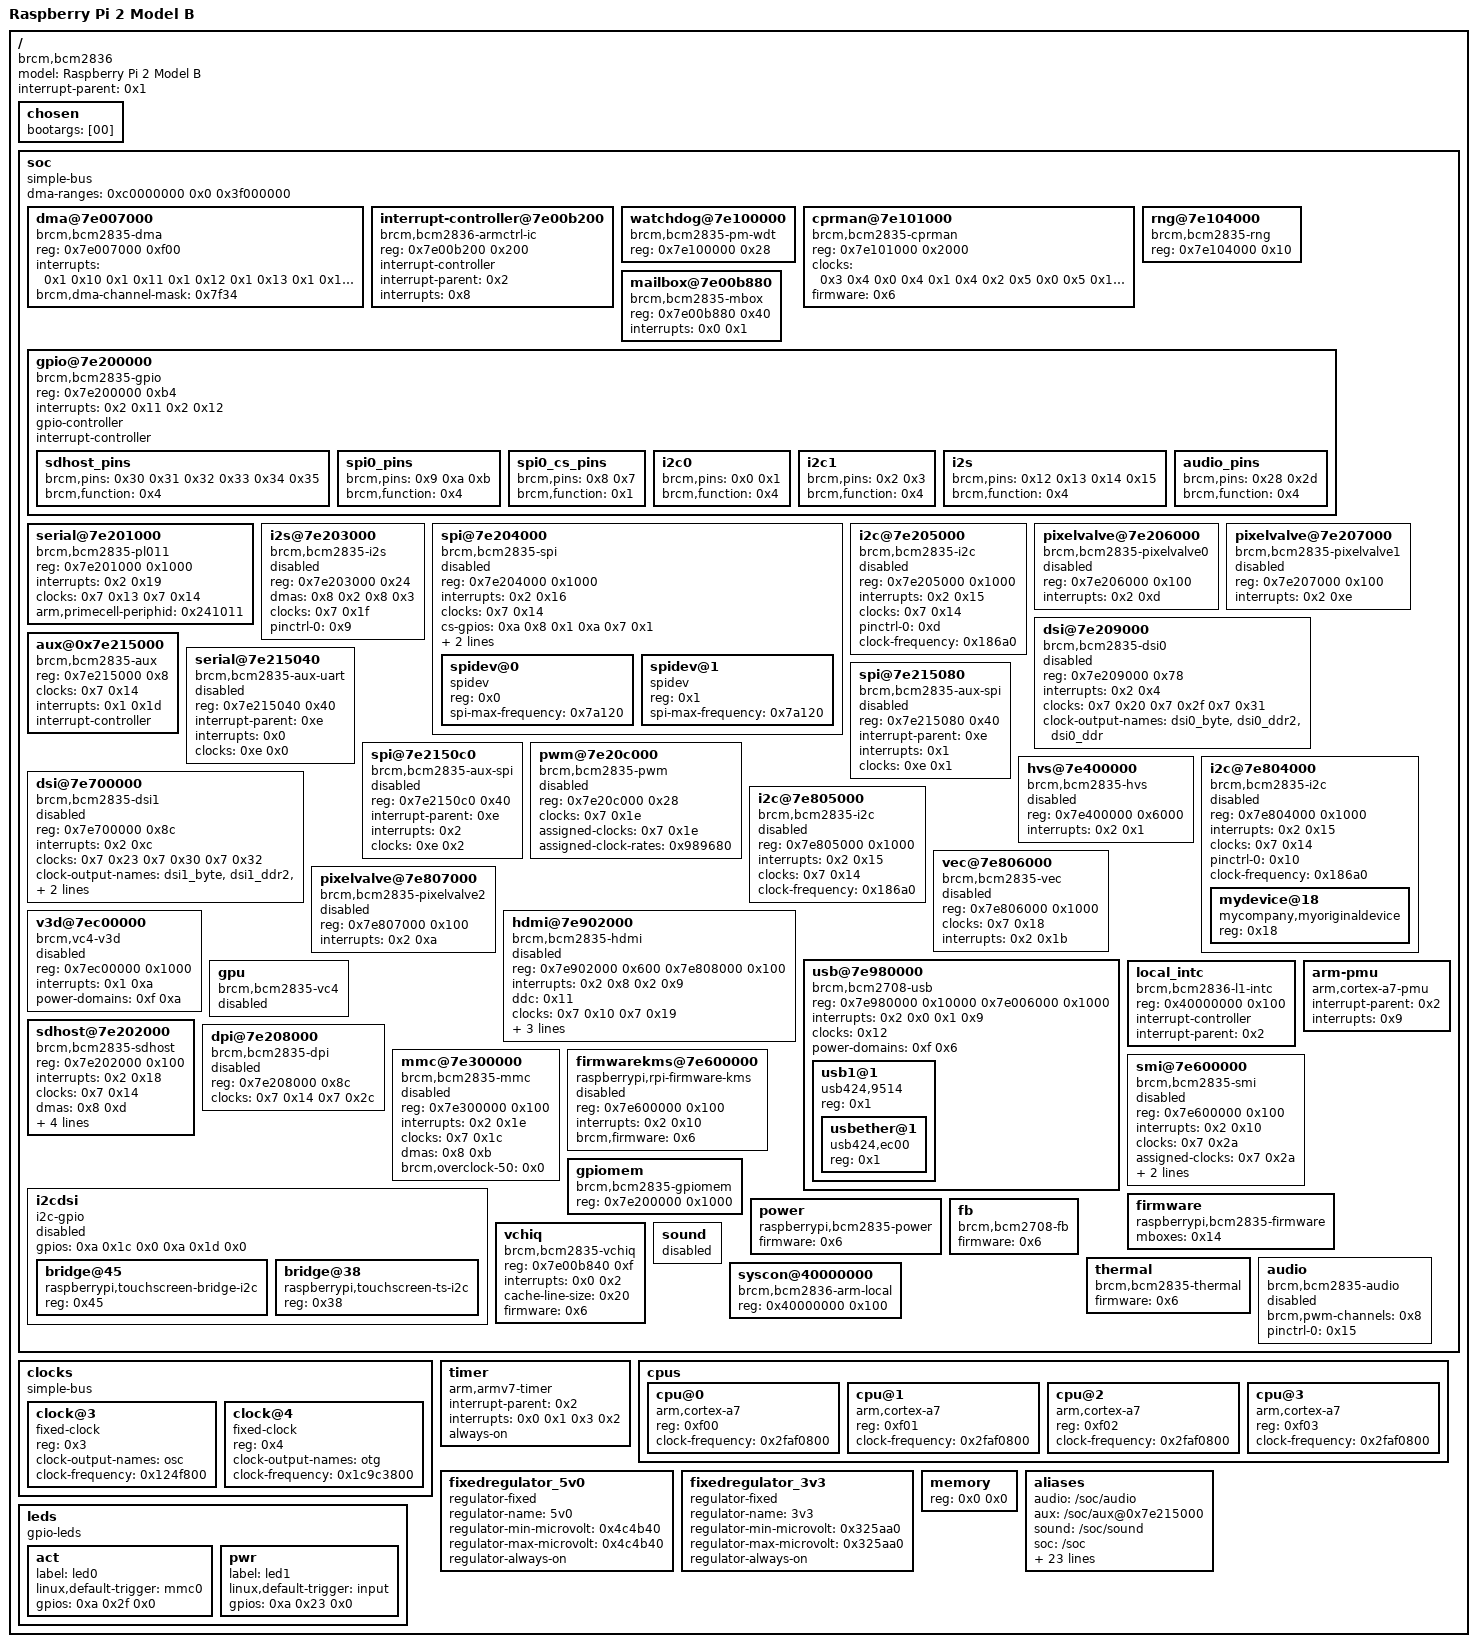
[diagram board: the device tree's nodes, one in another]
/dts-v1/;

/memreserve/	0x0000000000000000 0x0000000000001000;
/ {
	compatible = "brcm,bcm2836";
	model = "Raspberry Pi 2 Model B";
	interrupt-parent = <0x1>;
	#address-cells = <0x1>;
	#size-cells = <0x1>;

	chosen {
		bootargs = [00];
	};

	soc {
		compatible = "simple-bus";
		#address-cells = <0x1>;
		#size-cells = <0x1>;
		ranges = <0x7e000000 0x3f000000 0x1000000 0x40000000 0x40000000 0x40000>;
		dma-ranges = <0xc0000000 0x0 0x3f000000>;
		phandle = <0x27>;

		dma@7e007000 {
			compatible = "brcm,bcm2835-dma";
			reg = <0x7e007000 0xf00>;
			interrupts = <0x1 0x10 0x1 0x11 0x1 0x12 0x1 0x13 0x1 0x14 0x1 0x15 0x1 0x16 0x1 0x17 0x1 0x18 0x1 0x19 0x1 0x1a 0x1 0x1b 0x1 0x1b 0x1 0x1b 0x1 0x1b 0x1 0x1c>;
			interrupt-names = "dma0", "dma1", "dma2", "dma3", "dma4", "dma5", "dma6", "dma7", "dma8", "dma9", "dma10", "dma11", "dma12", "dma13", "dma14", "dma-shared-all";
			#dma-cells = <0x1>;
			brcm,dma-channel-mask = <0x7f34>;
			phandle = <0x8>;
		};

		interrupt-controller@7e00b200 {
			compatible = "brcm,bcm2836-armctrl-ic";
			reg = <0x7e00b200 0x200>;
			interrupt-controller;
			#interrupt-cells = <0x2>;
			interrupt-parent = <0x2>;
			interrupts = <0x8>;
			phandle = <0x1>;
		};

		watchdog@7e100000 {
			compatible = "brcm,bcm2835-pm-wdt";
			reg = <0x7e100000 0x28>;
			phandle = <0x24>;
		};

		cprman@7e101000 {
			compatible = "brcm,bcm2835-cprman";
			#clock-cells = <0x1>;
			reg = <0x7e101000 0x2000>;
			clocks = <0x3 0x4 0x0 0x4 0x1 0x4 0x2 0x5 0x0 0x5 0x1 0x5 0x2>;
			firmware = <0x6>;
			phandle = <0x7>;
		};

		rng@7e104000 {
			compatible = "brcm,bcm2835-rng";
			reg = <0x7e104000 0x10>;
			phandle = <0x25>;
		};

		mailbox@7e00b880 {
			compatible = "brcm,bcm2835-mbox";
			reg = <0x7e00b880 0x40>;
			interrupts = <0x0 0x1>;
			#mbox-cells = <0x0>;
			phandle = <0x14>;
		};

		gpio@7e200000 {
			compatible = "brcm,bcm2835-gpio";
			reg = <0x7e200000 0xb4>;
			interrupts = <0x2 0x11 0x2 0x12>;
			gpio-controller;
			#gpio-cells = <0x2>;
			interrupt-controller;
			#interrupt-cells = <0x2>;
			phandle = <0xa>;

			sdhost_pins {
				brcm,pins = <0x30 0x31 0x32 0x33 0x34 0x35>;
				brcm,function = <0x4>;
				phandle = <0x13>;
			};

			spi0_pins {
				brcm,pins = <0x9 0xa 0xb>;
				brcm,function = <0x4>;
				phandle = <0xb>;
			};

			spi0_cs_pins {
				brcm,pins = <0x8 0x7>;
				brcm,function = <0x1>;
				phandle = <0xc>;
			};

			i2c0 {
				brcm,pins = <0x0 0x1>;
				brcm,function = <0x4>;
				phandle = <0xd>;
			};

			i2c1 {
				brcm,pins = <0x2 0x3>;
				brcm,function = <0x4>;
				phandle = <0x10>;
			};

			i2s {
				brcm,pins = <0x12 0x13 0x14 0x15>;
				brcm,function = <0x4>;
				phandle = <0x9>;
			};

			audio_pins {
				brcm,pins = <0x28 0x2d>;
				brcm,function = <0x4>;
				phandle = <0x15>;
			};
		};

		serial@7e201000 {
			compatible = "brcm,bcm2835-pl011", "arm,pl011", "arm,primecell";
			reg = <0x7e201000 0x1000>;
			interrupts = <0x2 0x19>;
			clocks = <0x7 0x13 0x7 0x14>;
			clock-names = "uartclk", "apb_pclk";
			arm,primecell-periphid = <0x241011>;
			status = "okay";
			phandle = <0x1b>;
		};

		i2s@7e203000 {
			compatible = "brcm,bcm2835-i2s";
			reg = <0x7e203000 0x24>;
			dmas = <0x8 0x2 0x8 0x3>;
			dma-names = "tx", "rx";
			status = "disabled";
			#sound-dai-cells = <0x0>;
			clocks = <0x7 0x1f>;
			pinctrl-names = "default";
			pinctrl-0 = <0x9>;
			phandle = <0x1d>;
		};

		spi@7e204000 {
			compatible = "brcm,bcm2835-spi";
			reg = <0x7e204000 0x1000>;
			interrupts = <0x2 0x16>;
			clocks = <0x7 0x14>;
			#address-cells = <0x1>;
			#size-cells = <0x0>;
			status = "disabled";
			cs-gpios = <0xa 0x8 0x1 0xa 0x7 0x1>;
			dmas = <0x8 0x6 0x8 0x7>;
			dma-names = "tx", "rx";
			pinctrl-names = "default";
			pinctrl-0 = <0xb 0xc>;
			phandle = <0x1e>;

			spidev@0 {
				compatible = "spidev";
				reg = <0x0>;
				#address-cells = <0x1>;
				#size-cells = <0x0>;
				spi-max-frequency = <0x7a120>;
				phandle = <0x28>;
			};

			spidev@1 {
				compatible = "spidev";
				reg = <0x1>;
				#address-cells = <0x1>;
				#size-cells = <0x0>;
				spi-max-frequency = <0x7a120>;
				phandle = <0x29>;
			};
		};

		i2c@7e205000 {
			compatible = "brcm,bcm2835-i2c";
			reg = <0x7e205000 0x1000>;
			interrupts = <0x2 0x15>;
			clocks = <0x7 0x14>;
			#address-cells = <0x1>;
			#size-cells = <0x0>;
			status = "disabled";
			pinctrl-names = "default";
			pinctrl-0 = <0xd>;
			clock-frequency = <0x186a0>;
			phandle = <0x1f>;
		};

		pixelvalve@7e206000 {
			compatible = "brcm,bcm2835-pixelvalve0";
			reg = <0x7e206000 0x100>;
			interrupts = <0x2 0xd>;
			status = "disabled";
			phandle = <0x2a>;
		};

		pixelvalve@7e207000 {
			compatible = "brcm,bcm2835-pixelvalve1";
			reg = <0x7e207000 0x100>;
			interrupts = <0x2 0xe>;
			status = "disabled";
			phandle = <0x2b>;
		};

		dsi@7e209000 {
			compatible = "brcm,bcm2835-dsi0";
			reg = <0x7e209000 0x78>;
			interrupts = <0x2 0x4>;
			#address-cells = <0x1>;
			#size-cells = <0x0>;
			#clock-cells = <0x1>;
			clocks = <0x7 0x20 0x7 0x2f 0x7 0x31>;
			clock-names = "phy", "escape", "pixel";
			clock-output-names = "dsi0_byte", "dsi0_ddr2", "dsi0_ddr";
			status = "disabled";
			phandle = <0x4>;
		};

		aux@0x7e215000 {
			compatible = "brcm,bcm2835-aux";
			#clock-cells = <0x1>;
			reg = <0x7e215000 0x8>;
			clocks = <0x7 0x14>;
			interrupts = <0x1 0x1d>;
			interrupt-controller;
			#interrupt-cells = <0x1>;
			phandle = <0xe>;
		};

		serial@7e215040 {
			compatible = "brcm,bcm2835-aux-uart";
			reg = <0x7e215040 0x40>;
			interrupt-parent = <0xe>;
			interrupts = <0x0>;
			clocks = <0xe 0x0>;
			status = "disabled";
			phandle = <0x1c>;
		};

		spi@7e215080 {
			compatible = "brcm,bcm2835-aux-spi";
			reg = <0x7e215080 0x40>;
			interrupt-parent = <0xe>;
			interrupts = <0x1>;
			clocks = <0xe 0x1>;
			#address-cells = <0x1>;
			#size-cells = <0x0>;
			status = "disabled";
			phandle = <0x2c>;
		};

		spi@7e2150c0 {
			compatible = "brcm,bcm2835-aux-spi";
			reg = <0x7e2150c0 0x40>;
			interrupt-parent = <0xe>;
			interrupts = <0x2>;
			clocks = <0xe 0x2>;
			#address-cells = <0x1>;
			#size-cells = <0x0>;
			status = "disabled";
			phandle = <0x2d>;
		};

		pwm@7e20c000 {
			compatible = "brcm,bcm2835-pwm";
			reg = <0x7e20c000 0x28>;
			clocks = <0x7 0x1e>;
			assigned-clocks = <0x7 0x1e>;
			assigned-clock-rates = <0x989680>;
			#pwm-cells = <0x2>;
			status = "disabled";
			phandle = <0x2e>;
		};

		hvs@7e400000 {
			compatible = "brcm,bcm2835-hvs";
			reg = <0x7e400000 0x6000>;
			interrupts = <0x2 0x1>;
			status = "disabled";
			phandle = <0x2f>;
		};

		dsi@7e700000 {
			compatible = "brcm,bcm2835-dsi1";
			reg = <0x7e700000 0x8c>;
			interrupts = <0x2 0xc>;
			#address-cells = <0x1>;
			#size-cells = <0x0>;
			#clock-cells = <0x1>;
			clocks = <0x7 0x23 0x7 0x30 0x7 0x32>;
			clock-names = "phy", "escape", "pixel";
			clock-output-names = "dsi1_byte", "dsi1_ddr2", "dsi1_ddr";
			status = "disabled";
			power-domains = <0xf 0x12>;
			phandle = <0x5>;
		};

		i2c@7e804000 {
			compatible = "brcm,bcm2835-i2c";
			reg = <0x7e804000 0x1000>;
			interrupts = <0x2 0x15>;
			clocks = <0x7 0x14>;
			#address-cells = <0x1>;
			#size-cells = <0x0>;
			status = "disabled";
			pinctrl-names = "default";
			pinctrl-0 = <0x10>;
			clock-frequency = <0x186a0>;
			phandle = <0x20>;

			/* 自分用のデバイスを追加 */
			mydevice@18 {
				compatible = "mycompany,myoriginaldevice";
				reg = <0x18>;
			};

		};

		i2c@7e805000 {
			compatible = "brcm,bcm2835-i2c";
			reg = <0x7e805000 0x1000>;
			interrupts = <0x2 0x15>;
			clocks = <0x7 0x14>;
			#address-cells = <0x1>;
			#size-cells = <0x0>;
			status = "disabled";
			clock-frequency = <0x186a0>;
			phandle = <0x11>;
		};

		vec@7e806000 {
			compatible = "brcm,bcm2835-vec";
			reg = <0x7e806000 0x1000>;
			clocks = <0x7 0x18>;
			interrupts = <0x2 0x1b>;
			status = "disabled";
			phandle = <0x30>;
		};

		pixelvalve@7e807000 {
			compatible = "brcm,bcm2835-pixelvalve2";
			reg = <0x7e807000 0x100>;
			interrupts = <0x2 0xa>;
			status = "disabled";
			phandle = <0x31>;
		};

		hdmi@7e902000 {
			compatible = "brcm,bcm2835-hdmi";
			reg = <0x7e902000 0x600 0x7e808000 0x100>;
			interrupts = <0x2 0x8 0x2 0x9>;
			ddc = <0x11>;
			clocks = <0x7 0x10 0x7 0x19>;
			clock-names = "pixel", "hdmi";
			dmas = <0x8 0x11>;
			dma-names = "audio-rx";
			status = "disabled";
			power-domains = <0xf 0x5>;
			hpd-gpios = <0xa 0x2e 0x1>;
			phandle = <0x32>;
		};

		usb@7e980000 {
			compatible = "brcm,bcm2708-usb";
			reg = <0x7e980000 0x10000 0x7e006000 0x1000>;
			interrupts = <0x2 0x0 0x1 0x9>;
			#address-cells = <0x1>;
			#size-cells = <0x0>;
			clocks = <0x12>;
			clock-names = "otg";
			power-domains = <0xf 0x6>;
			phandle = <0x33>;

			usb1@1 {
				compatible = "usb424,9514";
				reg = <0x1>;
				#address-cells = <0x1>;
				#size-cells = <0x0>;

				usbether@1 {
					compatible = "usb424,ec00";
					reg = <0x1>;
					phandle = <0x34>;
				};
			};
		};

		v3d@7ec00000 {
			compatible = "brcm,vc4-v3d";
			reg = <0x7ec00000 0x1000>;
			interrupts = <0x1 0xa>;
			power-domains = <0xf 0xa>;
			status = "disabled";
			phandle = <0x35>;
		};

		gpu {
			compatible = "brcm,bcm2835-vc4";
			status = "disabled";
			phandle = <0x36>;
		};

		local_intc {
			compatible = "brcm,bcm2836-l1-intc";
			reg = <0x40000000 0x100>;
			interrupt-controller;
			#interrupt-cells = <0x1>;
			interrupt-parent = <0x2>;
			phandle = <0x2>;
		};

		arm-pmu {
			compatible = "arm,cortex-a7-pmu";
			interrupt-parent = <0x2>;
			interrupts = <0x9>;
		};

		sdhost@7e202000 {
			compatible = "brcm,bcm2835-sdhost";
			reg = <0x7e202000 0x100>;
			interrupts = <0x2 0x18>;
			clocks = <0x7 0x14>;
			dmas = <0x8 0xd>;
			dma-names = "rx-tx";
			brcm,overclock-50 = <0x0>;
			brcm,pio-limit = <0x1>;
			status = "okay";
			pinctrl-names = "default";
			pinctrl-0 = <0x13>;
			bus-width = <0x4>;
			phandle = <0x26>;
		};

		dpi@7e208000 {
			compatible = "brcm,bcm2835-dpi";
			reg = <0x7e208000 0x8c>;
			clocks = <0x7 0x14 0x7 0x2c>;
			clock-names = "core", "pixel";
			#address-cells = <0x1>;
			#size-cells = <0x0>;
			status = "disabled";
			phandle = <0x37>;
		};

		mmc@7e300000 {
			compatible = "brcm,bcm2835-mmc";
			reg = <0x7e300000 0x100>;
			interrupts = <0x2 0x1e>;
			clocks = <0x7 0x1c>;
			dmas = <0x8 0xb>;
			dma-names = "rx-tx";
			brcm,overclock-50 = <0x0>;
			status = "disabled";
			phandle = <0x38>;
		};

		firmwarekms@7e600000 {
			compatible = "raspberrypi,rpi-firmware-kms";
			reg = <0x7e600000 0x100>;
			interrupts = <0x2 0x10>;
			brcm,firmware = <0x6>;
			status = "disabled";
			phandle = <0x39>;
		};

		smi@7e600000 {
			compatible = "brcm,bcm2835-smi";
			reg = <0x7e600000 0x100>;
			interrupts = <0x2 0x10>;
			clocks = <0x7 0x2a>;
			assigned-clocks = <0x7 0x2a>;
			assigned-clock-rates = <0x7735940>;
			dmas = <0x8 0x4>;
			dma-names = "rx-tx";
			status = "disabled";
			phandle = <0x3a>;
		};

		i2cdsi {
			compatible = "i2c-gpio";
			#address-cells = <0x1>;
			#size-cells = <0x0>;
			status = "disabled";
			gpios = <0xa 0x1c 0x0 0xa 0x1d 0x0>;
			phandle = <0x3b>;

			bridge@45 {
				compatible = "raspberrypi,touchscreen-bridge-i2c";
				reg = <0x45>;
				phandle = <0x3c>;
			};

			bridge@38 {
				compatible = "raspberrypi,touchscreen-ts-i2c";
				reg = <0x38>;
				phandle = <0x3d>;
			};
		};

		gpiomem {
			compatible = "brcm,bcm2835-gpiomem";
			reg = <0x7e200000 0x1000>;
		};

		firmware {
			compatible = "raspberrypi,bcm2835-firmware";
			mboxes = <0x14>;
			phandle = <0x6>;
		};

		power {
			compatible = "raspberrypi,bcm2835-power";
			firmware = <0x6>;
			#power-domain-cells = <0x1>;
			phandle = <0xf>;
		};

		fb {
			compatible = "brcm,bcm2708-fb";
			firmware = <0x6>;
			status = "okay";
			phandle = <0x3e>;
		};

		vchiq {
			compatible = "brcm,bcm2835-vchiq";
			reg = <0x7e00b840 0xf>;
			interrupts = <0x0 0x2>;
			cache-line-size = <0x20>;
			firmware = <0x6>;
			phandle = <0x16>;
		};

		thermal {
			compatible = "brcm,bcm2835-thermal";
			firmware = <0x6>;
			phandle = <0x3f>;
		};

		audio {
			compatible = "brcm,bcm2835-audio";
			brcm,pwm-channels = <0x8>;
			status = "disabled";
			pinctrl-names = "default";
			pinctrl-0 = <0x15>;
			phandle = <0x23>;
		};

		sound {
			status = "disabled";
			phandle = <0x40>;
		};

		syscon@40000000 {
			compatible = "brcm,bcm2836-arm-local", "syscon";
			reg = <0x40000000 0x100>;
		};
	};

	clocks {
		compatible = "simple-bus";
		#address-cells = <0x1>;
		#size-cells = <0x0>;

		clock@3 {
			compatible = "fixed-clock";
			reg = <0x3>;
			#clock-cells = <0x0>;
			clock-output-names = "osc";
			clock-frequency = <0x124f800>;
			phandle = <0x3>;
		};

		clock@4 {
			compatible = "fixed-clock";
			reg = <0x4>;
			#clock-cells = <0x0>;
			clock-output-names = "otg";
			clock-frequency = <0x1c9c3800>;
			phandle = <0x12>;
		};
	};

	timer {
		compatible = "arm,armv7-timer";
		interrupt-parent = <0x2>;
		interrupts = <0x0 0x1 0x3 0x2>;
		always-on;
	};

	cpus {
		#address-cells = <0x1>;
		#size-cells = <0x0>;
		phandle = <0x41>;

		cpu@0 {
			device_type = "cpu";
			compatible = "arm,cortex-a7";
			reg = <0xf00>;
			clock-frequency = <0x2faf0800>;
			phandle = <0x17>;
		};

		cpu@1 {
			device_type = "cpu";
			compatible = "arm,cortex-a7";
			reg = <0xf01>;
			clock-frequency = <0x2faf0800>;
			phandle = <0x18>;
		};

		cpu@2 {
			device_type = "cpu";
			compatible = "arm,cortex-a7";
			reg = <0xf02>;
			clock-frequency = <0x2faf0800>;
			phandle = <0x19>;
		};

		cpu@3 {
			device_type = "cpu";
			compatible = "arm,cortex-a7";
			reg = <0xf03>;
			clock-frequency = <0x2faf0800>;
			phandle = <0x1a>;
		};
	};

	fixedregulator_5v0 {
		compatible = "regulator-fixed";
		regulator-name = "5v0";
		regulator-min-microvolt = <0x4c4b40>;
		regulator-max-microvolt = <0x4c4b40>;
		regulator-always-on;
		phandle = <0x42>;
	};

	fixedregulator_3v3 {
		compatible = "regulator-fixed";
		regulator-name = "3v3";
		regulator-min-microvolt = <0x325aa0>;
		regulator-max-microvolt = <0x325aa0>;
		regulator-always-on;
		phandle = <0x43>;
	};

	memory {
		device_type = "memory";
		reg = <0x0 0x0>;
	};

	aliases {
		audio = "/soc/audio";
		aux = "/soc/aux@0x7e215000";
		sound = "/soc/sound";
		soc = "/soc";
		dma = "/soc/dma@7e007000";
		intc = "/soc/interrupt-controller@7e00b200";
		watchdog = "/soc/watchdog@7e100000";
		random = "/soc/rng@7e104000";
		mailbox = "/soc/mailbox@7e00b880";
		gpio = "/soc/gpio@7e200000";
		uart0 = "/soc/serial@7e201000";
		sdhost = "/soc/sdhost@7e202000";
		i2s = "/soc/i2s@7e203000";
		spi0 = "/soc/spi@7e204000";
		i2c0 = "/soc/i2c@7e205000";
		uart1 = "/soc/serial@7e215040";
		spi1 = "/soc/spi@7e215080";
		spi2 = "/soc/spi@7e2150c0";
		mmc = "/soc/mmc@7e300000";
		i2c1 = "/soc/i2c@7e804000";
		i2c2 = "/soc/i2c@7e805000";
		usb = "/soc/usb@7e980000";
		leds = "/leds";
		fb = "/soc/fb";
		vchiq = "/soc/vchiq";
		thermal = "/soc/thermal";
		ethernet = "/soc/usb@7e980000/usb1@1/usbether@1";
	};

	leds {
		compatible = "gpio-leds";
		phandle = <0x44>;

		act {
			label = "led0";
			linux,default-trigger = "mmc0";
			gpios = <0xa 0x2f 0x0>;
			phandle = <0x21>;
		};

		pwr {
			label = "led1";
			linux,default-trigger = "input";
			gpios = <0xa 0x23 0x0>;
			phandle = <0x22>;
		};
	};

	__overrides__ {
		cache_line_size = [00 00 00 16 63 61 63 68 65 2d 6c 69 6e 65 2d 73 69 7a 65 3a 30 00];
		arm_freq = <0x17 0x636c6f63 0x6b2d6672 0x65717565 0x6e63793a 0x30000000 0x18636c 0x6f636b2d 0x66726571 0x75656e63 0x793a3000 0x19 0x636c6f63 0x6b2d6672 0x65717565 0x6e63793a 0x30000000 0x1a636c 0x6f636b2d 0x66726571 0x75656e63 0x793a3000>;
		uart0 = [00 00 00 1b 73 74 61 74 75 73 00];
		uart1 = [00 00 00 1c 73 74 61 74 75 73 00];
		i2s = [00 00 00 1d 73 74 61 74 75 73 00];
		spi = [00 00 00 1e 73 74 61 74 75 73 00];
		i2c0 = [00 00 00 1f 73 74 61 74 75 73 00];
		i2c1 = "", "", "", " status";
		i2c2_iknowwhatimdoing = [00 00 00 11 73 74 61 74 75 73 00];
		i2c0_baudrate = [00 00 00 1f 63 6c 6f 63 6b 2d 66 72 65 71 75 65 6e 63 79 3a 30 00];
		i2c1_baudrate = "", "", "", " clock-frequency:0";
		i2c2_baudrate = [00 00 00 11 63 6c 6f 63 6b 2d 66 72 65 71 75 65 6e 63 79 3a 30 00];
		act_led_gpio = "", "", "", "!gpios:4";
		act_led_activelow = "", "", "", "!gpios:8";
		act_led_trigger = "", "", "", "!linux,default-trigger";
		pwr_led_gpio = "", "", "", "\"gpios:4";
		pwr_led_activelow = "", "", "", "\"gpios:8";
		pwr_led_trigger = "", "", "", "\"linux,default-trigger";
		audio = "", "", "", "#status";
		watchdog = "", "", "", "$status";
		random = "", "", "", "%status";
		sd_overclock = "", "", "", "&brcm,overclock-50:0";
		sd_force_pio = "", "", "", "&brcm,force-pio?";
		sd_pio_limit = "", "", "", "&brcm,pio-limit:0";
		sd_debug = "", "", "", "&brcm,debug";
	};

	__symbols__ {
		soc = "/soc";
		dma = "/soc/dma@7e007000";
		intc = "/soc/interrupt-controller@7e00b200";
		watchdog = "/soc/watchdog@7e100000";
		cprman = "/soc/cprman@7e101000";
		clocks = "/soc/cprman@7e101000";
		random = "/soc/rng@7e104000";
		mailbox = "/soc/mailbox@7e00b880";
		gpio = "/soc/gpio@7e200000";
		sdhost_pins = "/soc/gpio@7e200000/sdhost_pins";
		spi0_pins = "/soc/gpio@7e200000/spi0_pins";
		spi0_cs_pins = "/soc/gpio@7e200000/spi0_cs_pins";
		i2c0_pins = "/soc/gpio@7e200000/i2c0";
		i2c1_pins = "/soc/gpio@7e200000/i2c1";
		i2s_pins = "/soc/gpio@7e200000/i2s";
		audio_pins = "/soc/gpio@7e200000/audio_pins";
		uart0 = "/soc/serial@7e201000";
		i2s = "/soc/i2s@7e203000";
		spi0 = "/soc/spi@7e204000";
		spi = "/soc/spi@7e204000";
		spidev0 = "/soc/spi@7e204000/spidev@0";
		spidev1 = "/soc/spi@7e204000/spidev@1";
		i2c0 = "/soc/i2c@7e205000";
		pixelvalve0 = "/soc/pixelvalve@7e206000";
		pixelvalve1 = "/soc/pixelvalve@7e207000";
		dsi0 = "/soc/dsi@7e209000";
		aux = "/soc/aux@0x7e215000";
		uart1 = "/soc/serial@7e215040";
		spi1 = "/soc/spi@7e215080";
		spi2 = "/soc/spi@7e2150c0";
		pwm = "/soc/pwm@7e20c000";
		hvs = "/soc/hvs@7e400000";
		dsi1 = "/soc/dsi@7e700000";
		i2c1 = "/soc/i2c@7e804000";
		i2c2 = "/soc/i2c@7e805000";
		vec = "/soc/vec@7e806000";
		pixelvalve2 = "/soc/pixelvalve@7e807000";
		hdmi = "/soc/hdmi@7e902000";
		usb = "/soc/usb@7e980000";
		ethernet = "/soc/usb@7e980000/usb1@1/usbether@1";
		v3d = "/soc/v3d@7ec00000";
		gpu = "/soc/gpu";
		vc4 = "/soc/gpu";
		local_intc = "/soc/local_intc";
		sdhost = "/soc/sdhost@7e202000";
		dpi = "/soc/dpi@7e208000";
		mmc = "/soc/mmc@7e300000";
		firmwarekms = "/soc/firmwarekms@7e600000";
		smi = "/soc/smi@7e600000";
		i2c_dsi = "/soc/i2cdsi";
		pitouchscreen_bridge = "/soc/i2cdsi/bridge@45";
		pitouchscreen_touch = "/soc/i2cdsi/bridge@38";
		firmware = "/soc/firmware";
		power = "/soc/power";
		fb = "/soc/fb";
		vchiq = "/soc/vchiq";
		thermal = "/soc/thermal";
		audio = "/soc/audio";
		sound = "/soc/sound";
		clk_osc = "/clocks/clock@3";
		clk_usb = "/clocks/clock@4";
		cpus = "/cpus";
		v7_cpu0 = "/cpus/cpu@0";
		v7_cpu1 = "/cpus/cpu@1";
		v7_cpu2 = "/cpus/cpu@2";
		v7_cpu3 = "/cpus/cpu@3";
		vdd_5v0_reg = "/fixedregulator_5v0";
		vdd_3v3_reg = "/fixedregulator_3v3";
		leds = "/leds";
		act_led = "/leds/act";
		pwr_led = "/leds/pwr";
	};
};
